# APM32F411 register map
File version: 1.0
CPU: CM4 r1p0, little endian, no MPU, no FPU, 3 interrupt priority bits
Registers are 32-bit, read-write, reset 0x0 unless marked. A register's access mark holds for its fields unless they carry their own. Offsets are from the block's base; [hi:lo] are bit positions; {n}, {i} and the like mark numbered series.

## RNG — Random number generator
Base 0x50060800
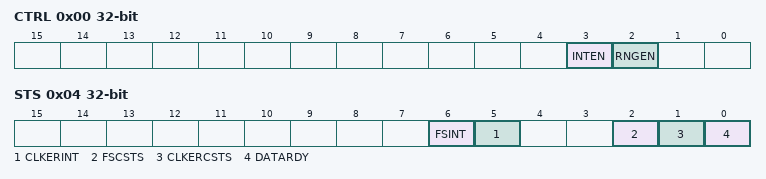
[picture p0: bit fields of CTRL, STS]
0x00 CTRL — control register
  [3] INTEN — Interrupt enable
  [2] RNGEN — Random number generator enable
0x04 STS access per field — status register
  [6] FSINT rw — Seed error interrupt status
  [5] CLKERINT rw — Clock error interrupt status
  [2] FSCSTS ro — Seed error current status
  [1] CLKERCSTS ro — Clock error current status
  [0] DATARDY ro — Data ready
0x08 DATA ro
  [31:0] DATA — Random data

## CRC — Cryptographic processor
Base 0x40023000
0x00 DATA reset 0xFFFFFFFF
0x04 INDATA — Independent Data register
  [7:0] INDATA
0x08 CTRL wo — Control register
  [0] RST — Reset CRC Calculation Unit

## GPIOC — General-purpose I/Os
Base 0x40020800
Same registers: GPIOD 0x40020C00, GPIOE 0x40021000, GPIOH 0x40021C00
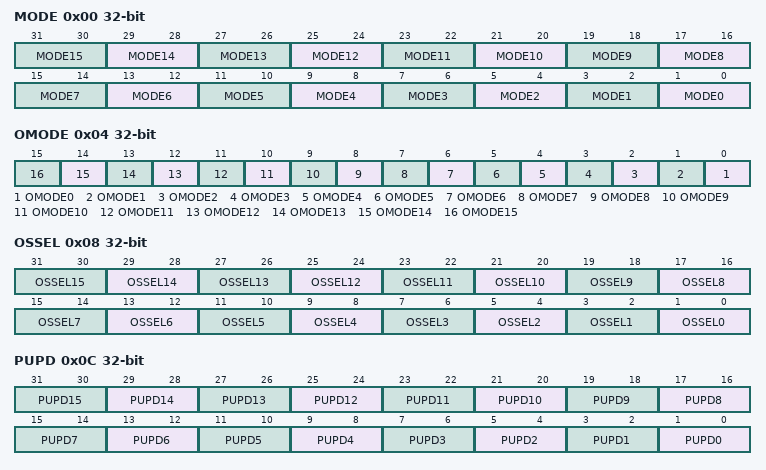
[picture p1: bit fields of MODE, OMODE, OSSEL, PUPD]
0x00 MODE — GPIO port mode register
  [2n+1:2n] MODE{n} (n=0..15) — Port x configuration bits (y = 0..15)
0x04 OMODE — GPIO port output type register
  [n] OMODE{n} (n=0..15) — Port x configuration bits (y = 0..15)
0x08 OSSEL — GPIO port output speed register
  [2n+1:2n] OSSEL{n} (n=0..15) — Port x configuration bits (y = 0..15)
0x0C PUPD — GPIO port pull-up/pull-down register
  [2n+1:2n] PUPD{n} (n=0..15) — Port x configuration bits (y = 0..15)
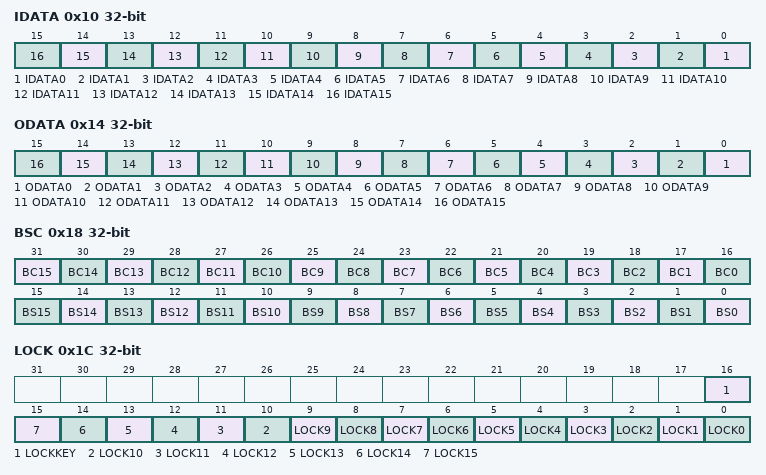
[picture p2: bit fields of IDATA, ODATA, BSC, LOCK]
0x10 IDATA ro — GPIO port input data register
  [n] IDATA{n} (n=0..15) — Port input data (y = 0..15)
0x14 ODATA — GPIO port output data register
  [n] ODATA{n} (n=0..15) — Port output data (y = 0..15)
0x18 BSC wo — GPIO port bit set/reset register
  [n+16] BC{n} (n=1..15) — Port x reset bit y (y = 0..15)
  [16] BC0 — Port x reset bit y (y= 0..15)
  [n] BS{n} (n=0..15) — Port x set bit y (y= 0..15)
0x1C LOCK — GPIO port configuration lock register
  [16] LOCKKEY
  [n] LOCK{n} (n=0..15) — Port x lock bit y (y= 0..15)
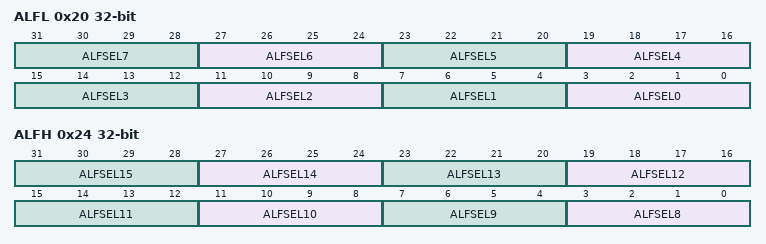
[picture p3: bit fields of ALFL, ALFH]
0x20 ALFL — GPIO alternate function low register
  [4n+3:4n] ALFSEL{n} (n=0..7) — Alternate function selection for port x bit y (y = 0..7)
0x24 ALFH — GPIO alternate function high register
  [4n-29:4n-32] ALFSEL{n} (n=8..15) — Alternate function selection for port x bit y (y = 8..15)

## GPIOB — General-purpose I/Os
Base 0x40020400
Registers as GPIOC; these are added or differ:
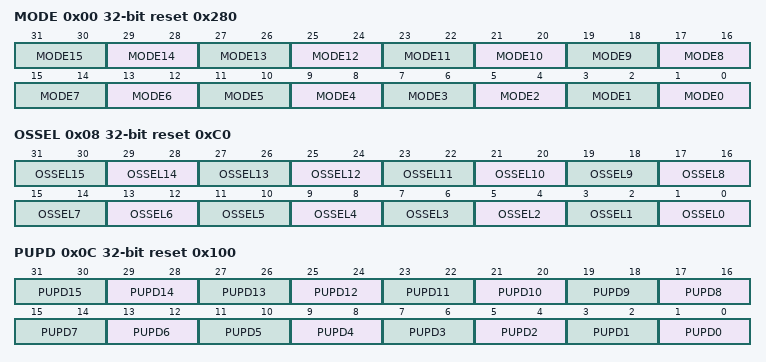
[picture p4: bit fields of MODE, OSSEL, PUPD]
0x00 MODE reset 0x280 — GPIO port mode register
  [2n+1:2n] MODE{n} (n=0..15) — Port x configuration bits (y = 0..15)
0x08 OSSEL reset 0xC0 — GPIO port output speed register
  [2n+1:2n] OSSEL{n} (n=0..15) — Port x configuration bits (y = 0..15)
0x0C PUPD reset 0x100 — GPIO port pull-up/pull-down register
  [2n+1:2n] PUPD{n} (n=0..15) — Port x configuration bits (y = 0..15)

## GPIOA — General-purpose I/Os
Base 0x40020000
Registers as GPIOC; these are added or differ:
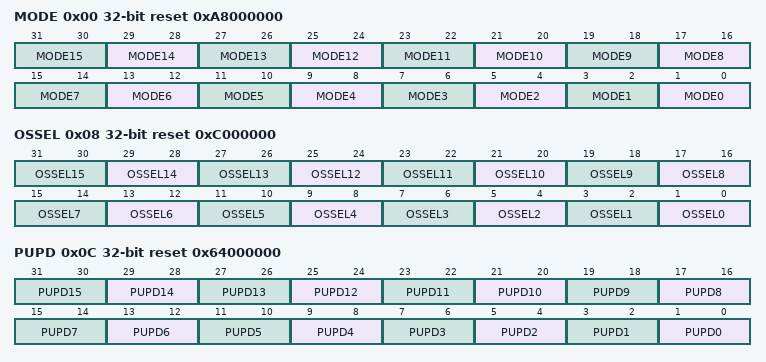
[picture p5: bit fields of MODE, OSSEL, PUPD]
0x00 MODE reset 0xA8000000 — GPIO port mode register
  [2n+1:2n] MODE{n} (n=0..15) — Port x configuration bits (y = 0..15)
0x08 OSSEL reset 0xC000000 — GPIO port output speed register
  [2n+1:2n] OSSEL{n} (n=0..15) — Port x configuration bits (y = 0..15)
0x0C PUPD reset 0x64000000 — GPIO port pull-up/pull-down register
  [2n+1:2n] PUPD{n} (n=0..15) — Port x configuration bits (y = 0..15)

## FMC — Flash memory controller
Base 0x40023C00
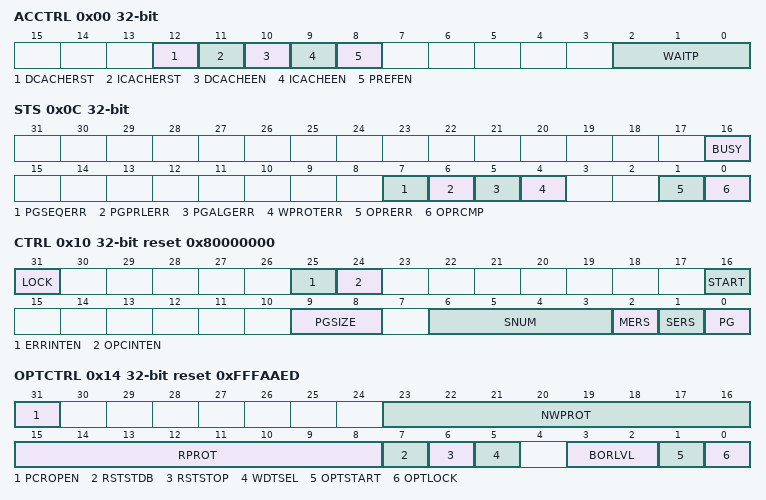
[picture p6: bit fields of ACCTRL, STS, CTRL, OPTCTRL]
0x00 ACCTRL access per field — Flash access control register
  [12] DCACHERST rw — Data cache reset
  [11] ICACHERST wo — Instruction cache reset
  [10] DCACHEEN rw — Data cache enable
  [9] ICACHEEN rw — Instruction cache enable
  [8] PREFEN rw — Prefetch enable
  [2:0] WAITP rw — Wait Period
0x04 KEY wo — Flash key register
0x08 OPTKEY wo — Flash option key register
  [31:0] OPTKEY — Option byte key
0x0C STS access per field — Status register
  [16] BUSY ro
  [7] PGSEQERR rw — Programming sequence error
  [6] PGPRLERR rw — Programming parallelism error
  [5] PGALGERR rw — Programming alignment error
  [4] WPROTERR rw — Write protection error
  [1] OPRERR rw — Operation error
  [0] OPRCMP rw — End of operation
0x10 CTRL reset 0x80000000 — Control register
  [31] LOCK
  [25] ERRINTEN — Error interrupt enable
  [24] OPCINTEN — End of operation interrupt enable
  [16] START
  [9:8] PGSIZE — Program size
  [6:3] SNUM — Sector number
  [2] MERS — Mass Erase
  [1] SERS — Sector Erase
  [0] PG — Programming
0x14 OPTCTRL reset 0xFFFAAED — Flash option control register
  [31] PCROPEN — PCROP Enable
  [23:16] NWPROT — Not write protect
  [15:8] RPROT — Read protect
  [7] RSTSTDB — nReset in STANDBY Mode
  [6] RSTSTOP — nRST_STOP User option mode
  [5] WDTSEL — Watchdog Select
  [3:2] BORLVL — Brownout reset Level
  [1] OPTSTART — Option start
  [0] OPTLOCK — Option lock
